# MCXA156 register map
Vendor: nxp.com; File version: 1.0
CPU: CM33 r2p0, little endian, no MPU, FPU, VTOR, 3 interrupt priority bits
Registers are 32-bit, read-write, reset 0x0 unless marked. A register's access mark holds for its fields unless they carry their own. Offsets are from the block's base; [hi:lo] are bit positions; {n}, {i} and the like mark numbered series; 'fields as' and 'values as' point back to an identical list.

## LPUART0 — LPUART
Base 0x4009F000
Same registers: LPUART1 0x400A0000, LPUART2 0x400A1000, LPUART3 0x400A2000, LPUART4 0x400A3000
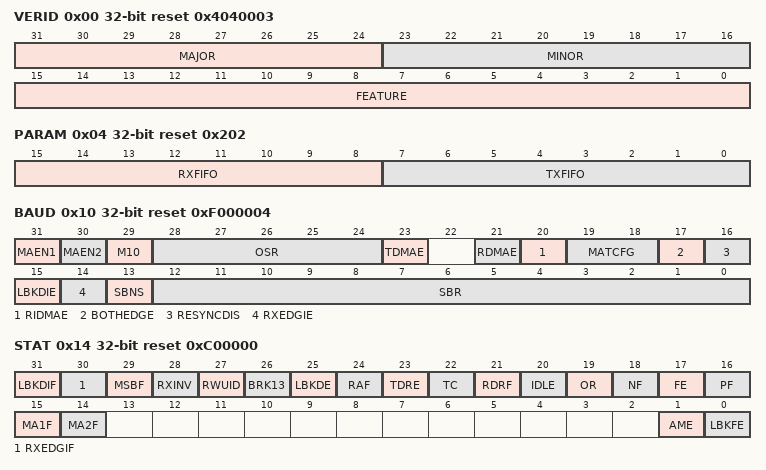
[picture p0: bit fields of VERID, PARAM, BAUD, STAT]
0x00 VERID ro reset 0x4040003 — Version ID
  [31:24] MAJOR — Major Version Number
  [23:16] MINOR — Minor Version Number
  [15:0] FEATURE — Feature Identification Number
    1=STANDARD (Standard feature set); 3=MODEM (Standard feature set with MODEM and IrDA support)
0x04 PARAM ro reset 0x202 — Parameter
  [15:8] RXFIFO — Receive FIFO Size
  [7:0] TXFIFO — Transmit FIFO Size
0x08 GLOBAL
  [1] RST — Software Reset
    0=NO_EFFECT (Not reset); 1=RESET
0x0C PINCFG — Pin Configuration
  [1:0] TRGSEL — Trigger Select
    0=DISABLED (Input trigger disabled); 1=TRG_RXD (Input trigger used instead of the RXD pin input); 2=TRG_CTS (Input trigger used instead of the CTS_B pin input); 3=TRG_TXD (Input trigger used to modulate the TXD pin output, which (after TXINV configuration) is internally ANDed with the input trigger)
0x10 BAUD reset 0xF000004 — Baud Rate
  [31] MAEN1 — Match Address Mode Enable 1
    0=DISABLED; 1=ENABLED
  [30] MAEN2 — Match Address Mode Enable 2
    0=DISABLED; 1=ENABLED
  [29] M10 — 10-Bit Mode Select
    0=DISABLED (Receiver and transmitter use 7-bit to 9-bit data characters); 1=ENABLED (Receiver and transmitter use 10-bit data characters)
  [28:24] OSR — Oversampling Ratio
    0=DEFAULT (Results in an OSR of 16); {v}=Results in an OSR of {v+1} (requires BAUD[BOTHEDGE] to be 1) (v=3..6); {v}=Results in an OSR of {v+1} (v=7..31)
  [23] TDMAE — Transmitter DMA Enable
    0=DISABLED; 1=ENABLED
  [21] RDMAE — Receiver Full DMA Enable
    0=DISABLED; 1=ENABLED
  [20] RIDMAE — Receiver Idle DMA Enable
    0=DISABLED; 1=ENABLED
  [19:18] MATCFG — Match Configuration
    0=ADDR_MATCH (Address match wake-up); 1=IDLE_MATCH (Idle match wake-up); 2=ONOFF_MATCH (Match on and match off); 3=RWU_MATCH (Enables RWU on data match and match on or off for the transmitter CTS input)
  [17] BOTHEDGE — Both Edge Sampling
    0=DISABLED (Rising edge); 1=ENABLED (Both rising and falling edges)
  [16] RESYNCDIS — Resynchronization Disable
    0=RESYNC (Enable); 1=NO_RESYNC (Disable)
  [15] LBKDIE — LIN Break Detect Interrupt Enable
    0=DISABLE; 1=ENABLE
  [14] RXEDGIE — RX Input Active Edge Interrupt Enable
    0=DISABLE; 1=ENABLE
  [13] SBNS — Stop Bit Number Select
    0=ONE (One stop bit); 1=TWO (Two stop bits)
  [12:0] SBR — Baud Rate Modulo Divisor
0x14 STAT reset 0xC00000 — Status
  [31] LBKDIF write-1-clears — LIN Break Detect Interrupt Flag
    on read: 0=NOT_DETECTED; 1=DETECTED
  [30] RXEDGIF write-1-clears — RXD Pin Active Edge Interrupt Flag
    on read: 0=NO_EDGE (Not occurred); 1=EDGE (Occurred)
  [29] MSBF — MSB First
    0=LSB_FIRST; 1=MSB_FIRST
  [28] RXINV — Receive Data Inversion
    0=NOT_INVERTED (Inverted); 1=INVERTED (Not inverted)
  [27] RWUID — Receive Wake Up Idle Detect
    0=IDLE_NOTSET (STAT[IDLE] does not become 1); 1=IDLE_SET (STAT[IDLE] becomes 1)
  [26] BRK13 — Break Character Generation Length
    0=SHORT (9 to 13 bit times); 1=LONG (12 to 15 bit times)
  [25] LBKDE — LIN Break Detection Enable
    0=DISABLED; 1=ENABLED
  [24] RAF ro — Receiver Active Flag
    0=IDLE (Idle, waiting for a start bit); 1=ACTIVE (Receiver active (RXD pin input not idle))
  [23] TDRE ro — Transmit Data Register Empty Flag
    0=TXDATA (Greater than watermark); 1=NO_TXDATA (Equal to or less than watermark)
  [22] TC ro — Transmission Complete Flag
    0=ACTIVE (Transmitter active); 1=COMPLETE (Transmitter idle)
  [21] RDRF ro — Receive Data Register Full Flag
    0=NO_RXDATA (Equal to or less than watermark); 1=RXDATA (Greater than watermark)
  [20] IDLE write-1-clears — Idle Line Flag
    on read: 0=NOIDLE (Idle line detected); 1=IDLE (Idle line not detected)
  [19] OR write-1-clears — Receiver Overrun Flag
    on read: 0=NO_OVERRUN; 1=OVERRUN (Receive overrun (new LPUART data is lost))
  [18] NF write-1-clears — Noise Flag
    on read: 0=NONOISE (No noise detected); 1=NOISE (Noise detected)
  [17] FE write-1-clears — Framing Error Flag
    on read: 0=NOERROR (No framing error detected (this does not guarantee that the framing is correct)); 1=ERROR (Framing error detected)
  [16] PF write-1-clears — Parity Error Flag
    on read: 0=NOPARITY (No parity error detected); 1=PARITY (Parity error detected)
  [15] MA1F write-1-clears — Match 1 Flag
    on read: 0=NOMATCH (Not equal to MA1); 1=MATCH (Equal to MA1)
  [14] MA2F write-1-clears — Match 2 Flag
    on read: 0=NOMATCH (Not equal to MA2); 1=MATCH (Equal to MA2)
  [1] AME — Address Mark Enable
    0=DISABLED; 1=ENABLED
  [0] LBKFE — LIN Break Flag Enable
    0=DISABLED; 1=ENABLED
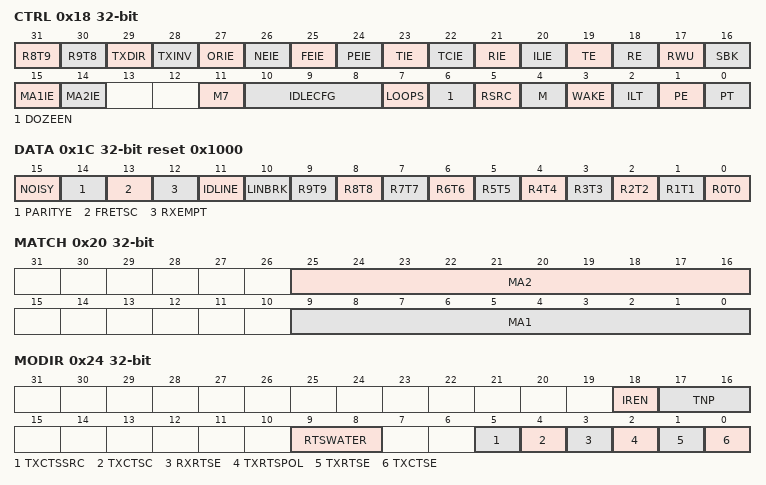
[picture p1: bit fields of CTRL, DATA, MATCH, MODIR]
0x18 CTRL — Control
  [31] R8T9 — Receive Bit 8 Transmit Bit 9
  [30] R9T8 — Receive Bit 9 Transmit Bit 8
  [29] TXDIR — TXD Pin Direction in Single-Wire Mode
    0=TX_INPUT (Input); 1=TX_OUTPUT (Output)
  [28] TXINV — Transmit Data Inversion
    0=NOT_INVERTED; 1=INVERTED
  [27] ORIE — Overrun Interrupt Enable
    0=DISABLED; 1=ENABLED
  [26] NEIE — Noise Error Interrupt Enable
    0=DISABLED; 1=ENABLED
  [25] FEIE — Framing Error Interrupt Enable
    0=DISABLED; 1=ENABLED
  [24] PEIE — Parity Error Interrupt Enable
    0=DISABLED; 1=ENABLED
  [23] TIE — Transmit Interrupt Enable
    0=DISABLED; 1=ENABLED
  [22] TCIE — Transmission Complete Interrupt Enable
    0=DISABLED; 1=ENABLED
  [21] RIE — Receiver Interrupt Enable
    0=DISABLED; 1=ENABLED
  [20] ILIE — Idle Line Interrupt Enable
    0=DISABLED; 1=ENABLED
  [19] TE — Transmitter Enable
    0=DISABLED; 1=ENABLED
  [18] RE — Receiver Enable
    0=DISABLED; 1=ENABLED
  [17] RWU — Receiver Wake-Up Control
    0=NO_EFFECT (Normal receiver operation); 1=RX_WAKEUP (LPUART receiver in standby, waiting for a wake-up condition)
  [16] SBK — Send Break
    0=NO_EFFECT (Normal transmitter operation); 1=TX_BREAK (Queue break character(s) to be sent)
  [15] MA1IE — Match 1 (MA1F) Interrupt Enable
    0=DISABLED; 1=ENABLED
  [14] MA2IE — Match 2 (MA2F) Interrupt Enable
    0=DISABLED; 1=ENABLED
  [11] M7 — 7-Bit Mode Select
    0=NO_EFFECT (8-bit to 10-bit); 1=DATA7 (7-bit)
  [10:8] IDLECFG — Idle Configuration
    0=IDLE_1 (1); 1=IDLE_2 (2); 2=IDLE_4 (4); 3=IDLE_8 (8); 4=IDLE_16 (16); 5=IDLE_32 (32); 6=IDLE_64 (64); 7=IDLE_128 (128)
  [7] LOOPS — Loop Mode Select
    0=NOFFECT (Normal operation: RXD and TXD use separate pins); 1=LOOPBACK (Loop mode or Single-Wire mode)
  [6] DOZEEN — Doze Mode
    0=ENABLED; 1=DISABLED
  [5] RSRC — Receiver Source Select
    0=NO_EFFECT (Internal Loopback mode); 1=ONEWIRE (Single-wire mode)
  [4] M — 9-Bit Or 8-Bit Mode Select
    0=DATA8 (8-bit); 1=DATA9 (9-bit)
  [3] WAKE — Receiver Wake-Up Method Select
    0=IDLE; 1=MARK
  [2] ILT — Idle Line Type Select
    0=FROM_START (After the start bit); 1=FROM_STOP (After the stop bit)
  [1] PE — Parity Enable
    0=DISABLED; 1=ENABLED
  [0] PT — Parity Type
    0=EVEN (Even parity); 1=ODD (Odd parity)
0x1C DATA reset 0x1000
  [15] NOISY ro — Noisy Data Received
    0=NO_NOISE (Received without noise); 1=NOISE (Received with noise)
  [14] PARITYE ro — Parity Error
    0=NO_PARITY (Received without a parity error); 1=PARITY (Received with a parity error)
  [13] FRETSC — Frame Error Transmit Special Character
    0=NO_ERROR (Received without a frame error on reads or transmits a normal character on writes); 1=ERROR (Received with a frame error on reads or transmits an idle or break character on writes)
  [12] RXEMPT ro — Receive Buffer Empty
    0=NOT_EMPTY (Valid data); 1=EMPTY (Invalid data and empty)
  [11] IDLINE ro — Idle Line
    0=NO_IDLE (Not idle); 1=IDLE
  [10] LINBRK ro — LIN Break
    0=NO_BREAK (Not detected); 1=BREAK (Detected)
  [n] R{n}T{n} (n=0..9) — Read receive FIFO bit {n} or write transmit FIFO bit {n}
0x20 MATCH — Match Address
  [25:16] MA2 — Match Address 2
  [9:0] MA1 — Match Address 1
0x24 MODIR — MODEM IrDA
  [18] IREN — IR Enable
    0=DISABLED; 1=ENABLED
  [17:16] TNP — Transmitter Narrow Pulse
    0=ONE_SAMPLE (1 / OSR); 1=TWO_SAMPLE (2 / OSR); 2=THREE_SAMPLE (3 / OSR); 3=FOUR_SAMPLE (4 / OSR)
  [9:8] RTSWATER — Receive RTS Configuration
  [5] TXCTSSRC — Transmit CTS Source
    0=CTS (The CTS_B pin); 1=MATCH (An internal connection to the receiver address match result)
  [4] TXCTSC — Transmit CTS Configuration
    0=START (Sampled at the start of each character); 1=IDLE (Sampled when the transmitter is idle)
  [3] RXRTSE — Receiver RTS Enable
    0=DISABLED; 1=ENABLED
  [2] TXRTSPOL — Transmitter RTS Polarity
    0=LOW (Active low); 1=HIGH (Active high)
  [1] TXRTSE — Transmitter RTS Enable
    0=DISABLED; 1=ENABLED
  [0] TXCTSE — Transmitter CTS Enable
    0=DISABLED; 1=ENABLED
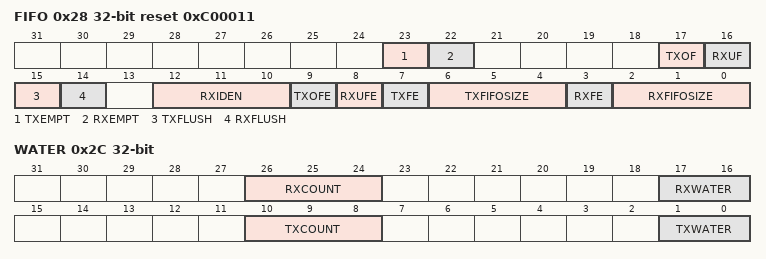
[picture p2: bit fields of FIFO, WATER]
0x28 FIFO reset 0xC00011
  [23] TXEMPT ro — Transmit FIFO Or Buffer Empty
    0=NOT_EMPTY; 1=EMPTY
  [22] RXEMPT ro — Receive FIFO Or Buffer Empty
    0=NOT_EMPTY; 1=EMPTY
  [17] TXOF write-1-clears — Transmitter FIFO Overflow Flag
    on read: 0=NO_OVERFLOW; 1=OVERFLOW
  [16] RXUF write-1-clears — Receiver FIFO Underflow Flag
    on read: 0=NO_UNDERFLOW; 1=UNDERFLOW
  [15] TXFLUSH — Transmit FIFO Flush
    0=NO_EFFECT; 1=TXFIFO_RST (All data flushed out)
  [14] RXFLUSH — Receive FIFO Flush
    0=NO_EFFECT; 1=RXFIFO_RST (All data flushed out)
  [12:10] RXIDEN — Receiver Idle Empty Enable
    0=DISABLED (Disable STAT[RDRF] to become 1 because of partially filled FIFO when the receiver is idle); 1=IDLE_1 (Enable STAT[RDRF] to become 1 because of partially filled FIFO when the receiver is idle for one character); 2=IDLE_2 (Enable STAT[RDRF] to become 1 because of partially filled FIFO when the receiver is idle for two characters); 3=IDLE_4 (Enable STAT[RDRF] to become 1 because of partially filled FIFO when the receiver is idle for four characters); 4=IDLE_8 (Enable STAT[RDRF] to become 1 because of partially filled FIFO when the receiver is idle for eight characters); 5=IDLE_16 (Enable STAT[RDRF] to become 1 because of partially filled FIFO when the receiver is idle for 16 characters); 6=IDLE_32 (Enable STAT[RDRF] to become 1 because of partially filled FIFO when the receiver is idle for 32 characters); 7=IDLE_64 (Enable STAT[RDRF] to become 1 because of partially filled FIFO when the receiver is idle for 64 characters)
  [9] TXOFE — Transmit FIFO Overflow Interrupt Enable
    0=DISABLED; 1=ENABLED
  [8] RXUFE — Receive FIFO Underflow Interrupt Enable
    0=DISABLED; 1=ENABLED
  [7] TXFE — Transmit FIFO Enable
    0=DISABLED; 1=ENABLED
  [6:4] TXFIFOSIZE ro — Transmit FIFO Buffer Depth
    0=FIFO_1 (1); 1=FIFO_4 (4); 2=FIFO_8 (8); 3=FIFO_16 (16); 4=FIFO_32 (32); 5=FIFO_64 (64); 6=FIFO_128 (128); 7=FIFO_256 (256)
  [3] RXFE — Receive FIFO Enable
    0=DISABLED; 1=ENABLED
  [2:0] RXFIFOSIZE ro — Receive FIFO Buffer Depth
    values as TXFIFOSIZE
0x2C WATER — Watermark
  [26:24] RXCOUNT ro — Receive Counter
  [17:16] RXWATER — Receive Watermark
  [10:8] TXCOUNT ro — Transmit Counter
  [1:0] TXWATER — Transmit Watermark
0x30 DATARO ro reset 0x1000 — Data Read-Only
  [15:0] DATA — Receive Data
